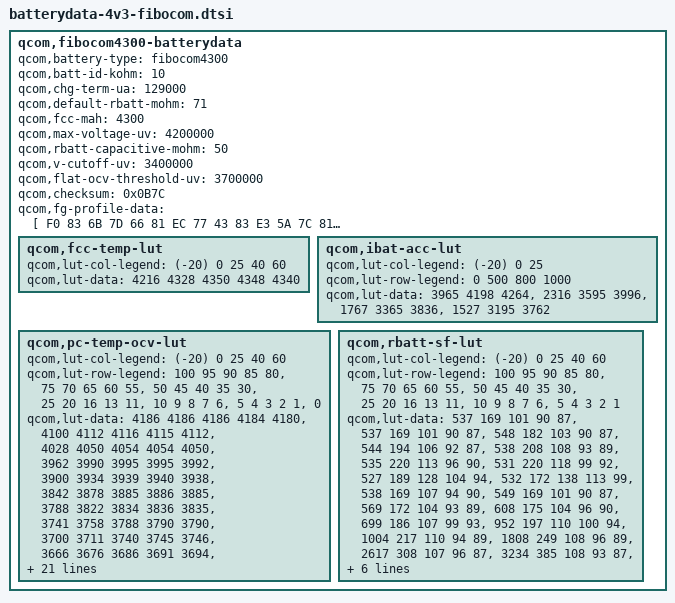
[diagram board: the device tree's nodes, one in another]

qcom,fibocom4300-batterydata {
	qcom,battery-type = "fibocom4300";
	qcom,batt-id-kohm = <10>;
	qcom,chg-term-ua = <129000>;
	qcom,default-rbatt-mohm = <71>;
	qcom,fcc-mah = <4300>;
	qcom,max-voltage-uv = <4200000>;
	qcom,rbatt-capacitive-mohm = <50>;
	qcom,v-cutoff-uv = <3400000>;
	qcom,flat-ocv-threshold-uv = <3700000>;
        qcom,checksum = <0x0B7C>;
	qcom,fg-profile-data = [
		F0 83 6B 7D
		66 81 EC 77
		43 83 E3 5A
		7C 81 33 8D
		E1 81 EC 98
		7B B5 F8 BB
		5B 12 E2 83
		4A 7C 63 80
		CF 75 50 83
		FD 5A 83 82
		E6 8E 12 82
		B6 9A 1A BE
		BE CB 55 0E
		96 0B E0 5A
		CE 6E 71 FD
		2A 31 7E 47
		CF 40 00 00
		DB 45 0F 32
		AF 31 00 00
		00 00 00 00
		00 00 00 00
		E3 6A 60 69
		9E 6D 47 83
		13 7C 23 70
		0B 74 8F 80
		DB 75 17 68
		BA 75 BF B3
		21 5B 69 B5
		6C A0 71 0C
		28 00 FF 36
		F0 11 30 03
		00 00 00 0E
	];
	qcom,fcc-temp-lut {
		qcom,lut-col-legend = <(-20) 0 25 40 60>;
		qcom,lut-data = <4216 4328 4350 4348 4340>;
	};

	qcom,ibat-acc-lut {
		qcom,lut-col-legend = <(-20) 0 25>;
		qcom,lut-row-legend = <0 500 800 1000>;
		qcom,lut-data = <3965 4198 4264>,
				<2316 3595 3996>,
				<1767 3365 3836>,
				<1527 3195 3762>;
				//<1176 2754 3585>,
				//<962 2340 3314>;
	};

	qcom,pc-temp-ocv-lut {
		qcom,lut-col-legend = <(-20) 0 25 40 60>;
		qcom,lut-row-legend = <100 95 90 85 80>,
					<75 70 65 60 55>,
					<50 45 40 35 30>,
					<25 20 16 13 11>,
					<10 9 8 7 6>,
					<5 4 3 2 1>,
					<0>;
		qcom,lut-data = <4186 4186 4186 4184 4180>,
				<4100 4112 4116 4115 4112>,
				<4028 4050 4054 4054 4050>,
				<3962 3990 3995 3995 3992>,
				<3900 3934 3939 3940 3938>,
				<3842 3878 3885 3886 3885>,
				<3788 3822 3834 3836 3835>,
				<3741 3758 3788 3790 3790>,
				<3700 3711 3740 3745 3746>,
				<3666 3676 3686 3691 3694>,
				<3637 3651 3658 3663 3666>,
				<3611 3630 3640 3644 3648>,
				<3588 3612 3623 3628 3632>,
				<3565 3596 3608 3614 3618>,
				<3542 3580 3594 3598 3602>,
				<3520 3562 3576 3575 3572>,
				<3497 3538 3549 3549 3546>,
				<3478 3507 3518 3519 3518>,
				<3460 3477 3487 3488 3488>,
				<3446 3458 3466 3468 3468>,
				<3438 3452 3460 3462 3462>,
				<3428 3444 3456 3458 3458>,
				<3418 3438 3452 3454 3454>,
				<3408 3432 3448 3450 3450>,
				<3398 3424 3442 3446 3446>,
				<3386 3417 3436 3440 3440>,
				<3374 3408 3430 3432 3434>,
				<3360 3394 3419 3423 3422>,
				<3344 3374 3400 3403 3400>,
				<3324 3346 3360 3360 3358>,
				<3300 3300 3300 3300 3300>;					
	};

	qcom,rbatt-sf-lut {
		qcom,lut-col-legend = <(-20) 0 25 40 60>;
		qcom,lut-row-legend = <100 95 90 85 80>,
					<75 70 65 60 55>,
					<50 45 40 35 30>,
					<25 20 16 13 11>,
					<10 9 8 7 6>,
					<5 4 3 2 1>;
		qcom,lut-data = <537 169 101 90 87>,
				<537 169 101 90 87>,
				<548 182 103 90 87>,
				<544 194 106 92 87>,
				<538 208 108 93 89>,
				<535 220 113 96 90>,
				<531 220 118 99 92>,
				<527 189 128 104 94>,
				<532 172 138 113 99>,
				<538 169 107 94 90>,
				<549 169 101 90 87>,
				<569 172 104 93 89>,
				<608 175 104 96 90>,
				<699 186 107 99 93>,
				<952 197 110 100 94>,
				<1004 217 110 94 89>,
				<1808 249 108 96 89>,
				<2617 308 107 96 87>,
				<3234 385 108 93 87>,
				<3721 430 110 93 89>,
				<4004 527 113 94 89>,
				<4659 608 114 96 90>,
				<5687 651 120 97 92>,
				<6685 714 127 100 92>,
				<7354 750 134 103 92>,
				<8218 801 144 106 93>,
				<9115 823 152 110 94>,
				<10394 846 165 115 97>,
				<14690 864 170 118 96>,
				<18552 880 180 118 96>;
	};
};
/* TEST_DB_ID=TEST_ID_NOT_SET */
